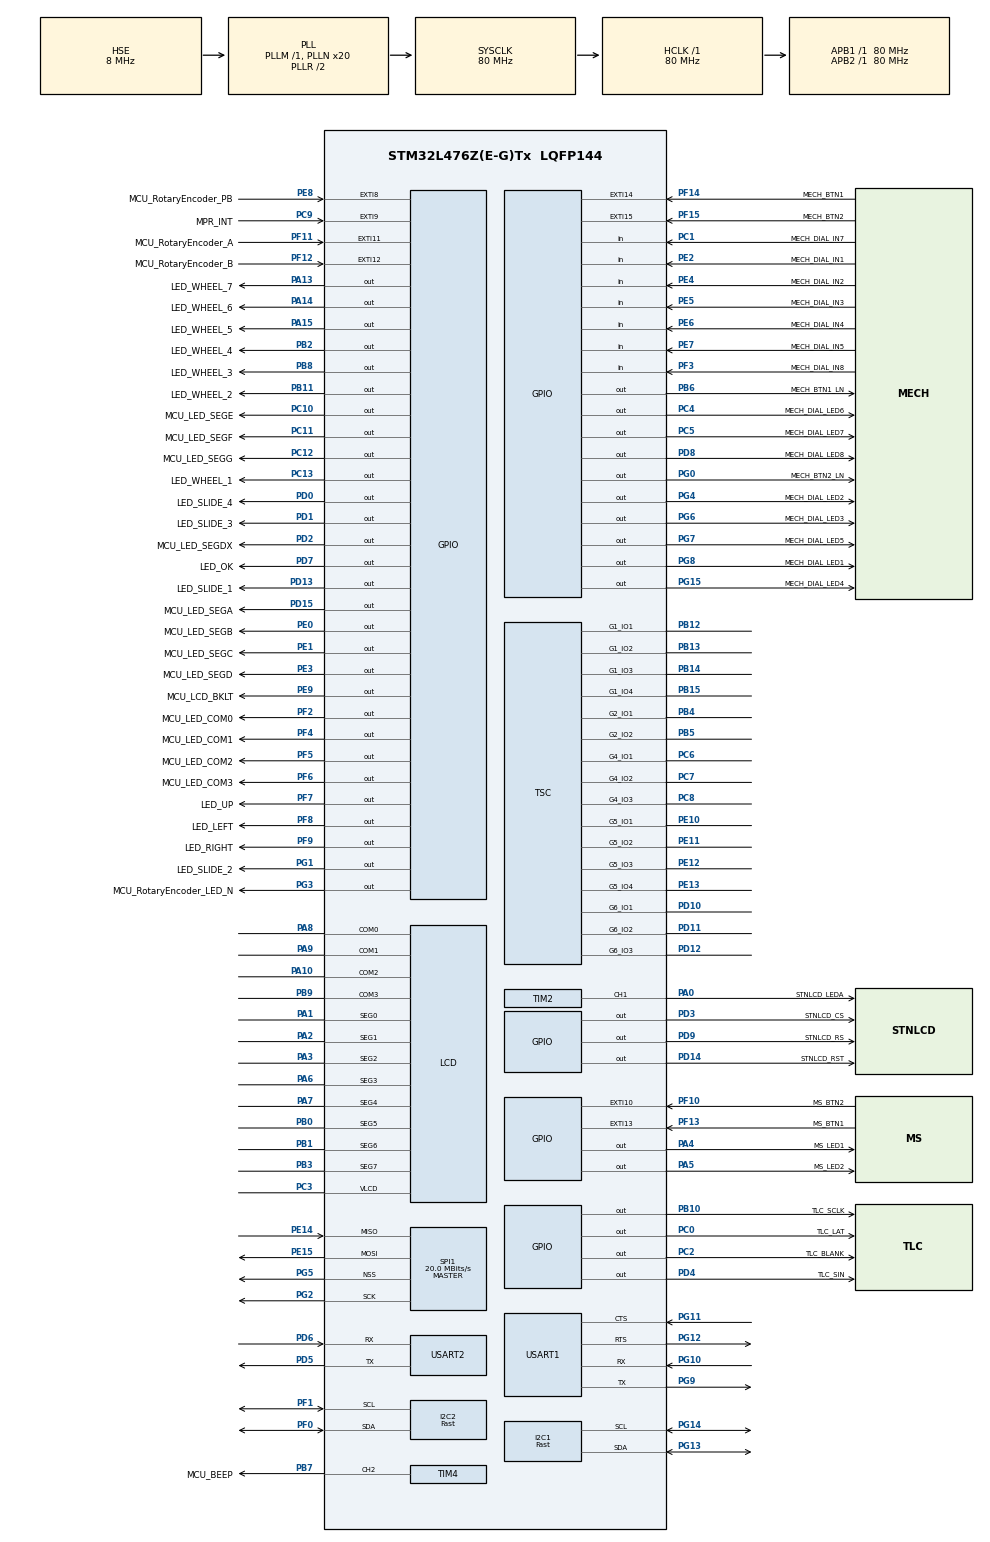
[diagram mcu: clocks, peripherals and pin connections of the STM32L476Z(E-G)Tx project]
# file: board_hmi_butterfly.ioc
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Dma.Request0=USART1_RX
Dma.Request1=USART2_RX
Dma.USART1_RX.0.Direction=DMA_PERIPH_TO_MEMORY
Dma.USART1_RX.0.Instance=DMA1_Channel5
Dma.USART1_RX.0.MemDataAlignment=DMA_MDATAALIGN_BYTE
Dma.USART1_RX.0.MemInc=DMA_MINC_ENABLE
Dma.USART1_RX.0.Mode=DMA_NORMAL
Dma.USART1_RX.0.PeriphDataAlignment=DMA_PDATAALIGN_BYTE
Dma.USART1_RX.0.PeriphInc=DMA_PINC_DISABLE
Dma.USART1_RX.0.Priority=DMA_PRIORITY_LOW
Dma.USART2_RX.1.Direction=DMA_PERIPH_TO_MEMORY
Dma.USART2_RX.1.Instance=DMA1_Channel6
Dma.USART2_RX.1.MemDataAlignment=DMA_MDATAALIGN_BYTE
Dma.USART2_RX.1.MemInc=DMA_MINC_ENABLE
Dma.USART2_RX.1.Mode=DMA_NORMAL
Dma.USART2_RX.1.PeriphDataAlignment=DMA_PDATAALIGN_BYTE
Dma.USART2_RX.1.PeriphInc=DMA_PINC_DISABLE
Dma.USART2_RX.1.Priority=DMA_PRIORITY_LOW
FREERTOS.Tasks01=defaultTask,0,128,StartDefaultTask,Default,NULL,Dynamic,NULL,NULL
FREERTOS.configCHECK_FOR_STACK_OVERFLOW=1
FREERTOS.configTIMER_TASK_PRIORITY=3
FREERTOS.configTOTAL_HEAP_SIZE=32768
FREERTOS.configUSE_TIMERS=1
I2C1.I2C_Speed_Mode=I2C_Fast
I2C1.Timing=0x00702991
I2C2.I2C_Speed_Mode=I2C_Fast
I2C2.Timing=0x00702991
LCD.Bias=LCD_BIAS_1_3
LCD.Contrast=LCD_CONTRASTLEVEL_5
LCD.Divider=LCD_DIVIDER_24
LCD.HighDrive=LCD_HIGHDRIVE_ENABLE
LCD.Prescaler=LCD_PRESCALER_4
Mcu.Family=STM32L4
Mcu.Name=STM32L476Z(E-G)Tx
Mcu.Package=LQFP144
NVIC.DMA1_Channel5_IRQn=true\:5\:0\:false\:false\:true\:true\:false
NVIC.DMA1_Channel6_IRQn=true\:5\:0\:false\:false\:true\:true\:false
NVIC.EXTI15_10_IRQn=true\:5\:0\:false\:false\:true\:true\:true
NVIC.EXTI9_5_IRQn=true\:5\:0\:false\:false\:true\:true\:true
NVIC.PriorityGroup=NVIC_PRIORITYGROUP_4
NVIC.RTC_Alarm_IRQn=true\:5\:0\:false\:false\:true\:true\:true
NVIC.USART1_IRQn=true\:5\:0\:false\:false\:true\:true\:true
NVIC.USART2_IRQn=true\:5\:0\:false\:false\:true\:true\:true
PA0.GPIO_Label=STNLCD_LEDA
PA0.Signal=S_TIM2_CH1
PA1.Mode=SEG0
PA1.Signal=LCD_SEG0
PA10.Mode=1/4 Duty Cycle
PA10.Signal=LCD_COM2
PA13\ (JTMS-SWDIO).GPIO_Label=LED_WHEEL_7
PA13\ (JTMS-SWDIO).GPIO_ModeDefaultOutputPP=GPIO_MODE_OUTPUT_OD
PA13\ (JTMS-SWDIO).PinState=GPIO_PIN_SET
PA13\ (JTMS-SWDIO).Signal=GPIO_Output
PA14\ (JTCK-SWCLK).GPIO_Label=LED_WHEEL_6
PA14\ (JTCK-SWCLK).GPIO_ModeDefaultOutputPP=GPIO_MODE_OUTPUT_OD
PA14\ (JTCK-SWCLK).PinState=GPIO_PIN_SET
PA14\ (JTCK-SWCLK).Signal=GPIO_Output
PA15\ (JTDI).GPIO_Label=LED_WHEEL_5
PA15\ (JTDI).GPIO_ModeDefaultOutputPP=GPIO_MODE_OUTPUT_OD
PA15\ (JTDI).PinState=GPIO_PIN_SET
PA15\ (JTDI).Signal=GPIO_Output
PA2.Mode=SEG1
PA2.Signal=LCD_SEG1
PA3.Mode=SEG2
PA3.Signal=LCD_SEG2
PA4.GPIO_Label=MS_LED1
PA4.GPIO_ModeDefaultOutputPP=GPIO_MODE_OUTPUT_OD
PA4.PinState=GPIO_PIN_SET
PA4.Signal=GPIO_Output
PA5.GPIO_Label=MS_LED2
PA5.GPIO_ModeDefaultOutputPP=GPIO_MODE_OUTPUT_OD
PA5.PinState=GPIO_PIN_SET
PA5.Signal=GPIO_Output
PA6.Mode=SEG3
PA6.Signal=LCD_SEG3
PA7.Mode=SEG4
PA7.Signal=LCD_SEG4
PA8.Mode=1/4 Duty Cycle
PA8.Signal=LCD_COM0
PA9.Mode=1/4 Duty Cycle
PA9.Signal=LCD_COM1
PB0.Mode=SEG5
PB0.Signal=LCD_SEG5
PB1.Mode=SEG6
PB1.Signal=LCD_SEG6
PB10.GPIO_Label=TLC_SCLK
PB10.GPIO_ModeDefaultOutputPP=GPIO_MODE_OUTPUT_OD
PB10.Signal=GPIO_Output
PB11.GPIO_Label=LED_WHEEL_2
PB11.GPIO_ModeDefaultOutputPP=GPIO_MODE_OUTPUT_OD
PB11.PinState=GPIO_PIN_SET
PB11.Signal=GPIO_Output
PB12.Mode=G1_IO1-Sampling
PB12.Signal=TSC_G1_IO1
PB13.Mode=G1_IO2-Channel
PB13.Signal=TSC_G1_IO2
PB14.Mode=G1_IO3-Channel
PB14.Signal=TSC_G1_IO3
PB15.Mode=G1_IO4-Channel
PB15.Signal=TSC_G1_IO4
PB2.GPIO_Label=LED_WHEEL_4
PB2.GPIO_ModeDefaultOutputPP=GPIO_MODE_OUTPUT_OD
PB2.PinState=GPIO_PIN_SET
PB2.Signal=GPIO_Output
PB3\ (JTDO-TRACESWO).Mode=SEG7
PB3\ (JTDO-TRACESWO).Signal=LCD_SEG7
PB4\ (NJTRST).Mode=G2_IO1-Sampling
PB4\ (NJTRST).Signal=TSC_G2_IO1
PB5.Mode=G2_IO2-Channel
PB5.Signal=TSC_G2_IO2
PB6.GPIO_Label=MECH_BTN1_LN
PB6.GPIO_ModeDefaultOutputPP=GPIO_MODE_OUTPUT_OD
PB6.PinState=GPIO_PIN_SET
PB6.Signal=GPIO_Output
PB7.GPIO_FM7=__NULL
PB7.GPIO_Label=MCU_BEEP
PB7.GPIO_ModeDefaultPP=GPIO_MODE_AF_PP
PB7.GPIO_Speed=GPIO_SPEED_FREQ_MEDIUM
PB7.Signal=S_TIM4_CH2
PB8.GPIO_Label=LED_WHEEL_3
PB8.GPIO_ModeDefaultOutputPP=GPIO_MODE_OUTPUT_OD
PB8.PinState=GPIO_PIN_SET
PB8.Signal=GPIO_Output
PB9.Mode=1/4 Duty Cycle
PB9.Signal=LCD_COM3
PC0.GPIO_Label=TLC_LAT
PC0.GPIO_ModeDefaultOutputPP=GPIO_MODE_OUTPUT_OD
PC0.Signal=GPIO_Output
PC1.GPIO_Label=MECH_DIAL_IN7
PC1.Signal=GPIO_Input
PC10.GPIO_Label=MCU_LED_SEGE
PC10.Signal=GPIO_Output
PC11.GPIO_Label=MCU_LED_SEGF
PC11.Signal=GPIO_Output
PC12.GPIO_Label=MCU_LED_SEGG
PC12.Signal=GPIO_Output
PC13.GPIO_Label=LED_WHEEL_1
PC13.GPIO_ModeDefaultOutputPP=GPIO_MODE_OUTPUT_OD
PC13.PinState=GPIO_PIN_SET
PC13.Signal=GPIO_Output
PC14-OSC32_IN\ (PC14).Mode=LSE-External-Oscillator
PC14-OSC32_IN\ (PC14).Signal=RCC_OSC32_IN
PC15-OSC32_OUT\ (PC15).Mode=LSE-External-Oscillator
PC15-OSC32_OUT\ (PC15).Signal=RCC_OSC32_OUT
PC2.GPIO_Label=TLC_BLANK
PC2.GPIO_ModeDefaultOutputPP=GPIO_MODE_OUTPUT_OD
PC2.GPIO_Speed=GPIO_SPEED_FREQ_LOW
PC2.PinState=GPIO_PIN_RESET
PC2.Signal=GPIO_Output
PC3.Mode=1/4 Duty Cycle
PC3.Signal=LCD_VLCD
PC4.GPIO_Label=MECH_DIAL_LED6
PC4.GPIO_ModeDefaultOutputPP=GPIO_MODE_OUTPUT_OD
PC4.PinState=GPIO_PIN_SET
PC4.Signal=GPIO_Output
PC5.GPIO_Label=MECH_DIAL_LED7
PC5.GPIO_ModeDefaultOutputPP=GPIO_MODE_OUTPUT_OD
PC5.PinState=GPIO_PIN_SET
PC5.Signal=GPIO_Output
PC6.Mode=G4_IO1-Sampling
PC6.Signal=TSC_G4_IO1
PC7.Mode=G4_IO2-Channel
PC7.Signal=TSC_G4_IO2
PC8.Mode=G4_IO3-Channel
PC8.Signal=TSC_G4_IO3
PC9.GPIO_Label=MPR_INT
PC9.GPIO_ModeDefaultEXTI=GPIO_MODE_IT_FALLING
PC9.Signal=GPXTI9
PD0.GPIO_Label=LED_SLIDE_4
PD0.GPIO_ModeDefaultOutputPP=GPIO_MODE_OUTPUT_OD
PD0.PinState=GPIO_PIN_SET
PD0.Signal=GPIO_Output
PD1.GPIO_Label=LED_SLIDE_3
PD1.GPIO_ModeDefaultOutputPP=GPIO_MODE_OUTPUT_OD
PD1.PinState=GPIO_PIN_SET
PD1.Signal=GPIO_Output
PD10.Mode=G6_IO1-Sampling
PD10.Signal=TSC_G6_IO1
PD11.Mode=G6_IO2-Channel
PD11.Signal=TSC_G6_IO2
PD12.Mode=G6_IO3-Channel
PD12.Signal=TSC_G6_IO3
PD13.GPIO_Label=LED_SLIDE_1
PD13.GPIO_ModeDefaultOutputPP=GPIO_MODE_OUTPUT_OD
PD13.PinState=GPIO_PIN_SET
PD13.Signal=GPIO_Output
PD14.GPIO_Label=STNLCD_RST
PD14.Signal=GPIO_Output
PD15.GPIO_Label=MCU_LED_SEGA
PD15.PinState=GPIO_PIN_RESET
PD15.Signal=GPIO_Output
PD2.GPIO_Label=MCU_LED_SEGDX
PD2.Signal=GPIO_Output
PD3.GPIO_Label=STNLCD_CS
PD3.Signal=GPIO_Output
PD4.GPIO_Label=TLC_SIN
PD4.Signal=GPIO_Output
PD5.Mode=Asynchronous
PD5.Signal=USART2_TX
PD6.Mode=Asynchronous
PD6.Signal=USART2_RX
PD7.GPIO_Label=LED_OK
PD7.GPIO_ModeDefaultOutputPP=GPIO_MODE_OUTPUT_OD
PD7.PinState=GPIO_PIN_SET
PD7.Signal=GPIO_Output
PD8.GPIO_Label=MECH_DIAL_LED8
PD8.GPIO_ModeDefaultOutputPP=GPIO_MODE_OUTPUT_OD
PD8.PinState=GPIO_PIN_SET
PD8.Signal=GPIO_Output
PD9.GPIO_Label=STNLCD_RS
PD9.Signal=GPIO_Output
PE0.GPIO_Label=MCU_LED_SEGB
PE0.Signal=GPIO_Output
PE1.GPIO_Label=MCU_LED_SEGC
PE1.Signal=GPIO_Output
PE10.Mode=G5_IO1-Sampling
PE10.Signal=TSC_G5_IO1
PE11.Mode=G5_IO2-Channel
PE11.Signal=TSC_G5_IO2
PE12.Mode=G5_IO3-Channel
PE12.Signal=TSC_G5_IO3
PE13.Mode=G5_IO4-Channel
PE13.Signal=TSC_G5_IO4
PE14.Mode=Full_Duplex_Master
PE14.Signal=SPI1_MISO
PE15.Mode=Full_Duplex_Master
PE15.Signal=SPI1_MOSI
PE2.GPIO_Label=MECH_DIAL_IN1
PE2.Signal=GPIO_Input
PE3.GPIO_Label=MCU_LED_SEGD
PE3.Signal=GPIO_Output
PE4.GPIO_Label=MECH_DIAL_IN2
PE4.Signal=GPIO_Input
PE5.GPIO_Label=MECH_DIAL_IN3
PE5.Signal=GPIO_Input
PE6.GPIO_Label=MECH_DIAL_IN4
PE6.Signal=GPIO_Input
PE7.GPIO_Label=MECH_DIAL_IN5
PE7.Signal=GPIO_Input
PE8.GPIO_Label=MCU_RotaryEncoder_PB
PE8.GPIO_ModeDefaultEXTI=GPIO_MODE_IT_RISING_FALLING
PE8.Signal=GPXTI8
PE9.GPIO_Label=MCU_LCD_BKLT
PE9.GPIO_PuPd=GPIO_NOPULL
PE9.Signal=GPIO_Output
PF0.Mode=I2C
PF0.Signal=I2C2_SDA
PF1.Mode=I2C
PF1.Signal=I2C2_SCL
PF10.GPIO_Label=MS_BTN2
PF10.GPIO_ModeDefaultEXTI=GPIO_MODE_IT_RISING_FALLING
PF10.Signal=GPXTI10
PF11.GPIO_Label=MCU_RotaryEncoder_A
PF11.GPIO_ModeDefaultEXTI=GPIO_MODE_IT_RISING_FALLING
PF11.Signal=GPXTI11
PF12.GPIO_Label=MCU_RotaryEncoder_B
PF12.GPIO_ModeDefaultEXTI=GPIO_MODE_IT_RISING_FALLING
PF12.Signal=GPXTI12
PF13.GPIO_Label=MS_BTN1
PF13.GPIO_ModeDefaultEXTI=GPIO_MODE_IT_RISING_FALLING
PF13.Signal=GPXTI13
PF14.GPIO_Label=MECH_BTN1
PF14.GPIO_ModeDefaultEXTI=GPIO_MODE_IT_RISING_FALLING
PF14.Signal=GPXTI14
PF15.GPIO_Label=MECH_BTN2
PF15.GPIO_ModeDefaultEXTI=GPIO_MODE_IT_RISING_FALLING
PF15.Signal=GPXTI15
PF2.GPIO_Label=MCU_LED_COM0
PF2.GPIO_Speed=GPIO_SPEED_FREQ_HIGH
PF2.PinState=GPIO_PIN_SET
PF2.Signal=GPIO_Output
PF3.GPIO_Label=MECH_DIAL_IN8
PF3.Signal=GPIO_Input
PF4.GPIO_Label=MCU_LED_COM1
PF4.GPIO_Speed=GPIO_SPEED_FREQ_HIGH
PF4.PinState=GPIO_PIN_SET
PF4.Signal=GPIO_Output
PF5.GPIO_Label=MCU_LED_COM2
PF5.GPIO_Speed=GPIO_SPEED_FREQ_HIGH
PF5.PinState=GPIO_PIN_SET
PF5.Signal=GPIO_Output
PF6.GPIO_Label=MCU_LED_COM3
PF6.GPIO_Speed=GPIO_SPEED_FREQ_HIGH
PF6.PinState=GPIO_PIN_SET
PF6.Signal=GPIO_Output
PF7.GPIO_Label=LED_UP
PF7.GPIO_ModeDefaultOutputPP=GPIO_MODE_OUTPUT_OD
PF7.PinState=GPIO_PIN_SET
PF7.Signal=GPIO_Output
PF8.GPIO_Label=LED_LEFT
PF8.GPIO_ModeDefaultOutputPP=GPIO_MODE_OUTPUT_OD
PF8.PinState=GPIO_PIN_SET
PF8.Signal=GPIO_Output
PF9.GPIO_Label=LED_RIGHT
PF9.GPIO_ModeDefaultOutputPP=GPIO_MODE_OUTPUT_OD
PF9.PinState=GPIO_PIN_SET
PF9.Signal=GPIO_Output
PG0.GPIO_Label=MECH_BTN2_LN
PG0.GPIO_ModeDefaultOutputPP=GPIO_MODE_OUTPUT_OD
PG0.PinState=GPIO_PIN_SET
PG0.Signal=GPIO_Output
PG1.GPIO_Label=LED_SLIDE_2
PG1.GPIO_ModeDefaultOutputPP=GPIO_MODE_OUTPUT_OD
PG1.PinState=GPIO_PIN_SET
PG1.Signal=GPIO_Output
PG10.Mode=Asynchronous
PG10.Signal=USART1_RX
PG11.Mode=CTS_RTS
PG11.Signal=USART1_CTS
PG12.Mode=CTS_RTS
PG12.Signal=USART1_RTS
PG13.Mode=I2C
PG13.Signal=I2C1_SDA
PG14.Mode=I2C
PG14.Signal=I2C1_SCL
PG15.GPIO_Label=MECH_DIAL_LED4
PG15.GPIO_ModeDefaultOutputPP=GPIO_MODE_OUTPUT_OD
PG15.PinState=GPIO_PIN_SET
PG15.Signal=GPIO_Output
PG2.Mode=Full_Duplex_Master
PG2.Signal=SPI1_SCK
PG3.GPIO_Label=MCU_RotaryEncoder_LED_N
PG3.GPIO_ModeDefaultOutputPP=GPIO_MODE_OUTPUT_OD
PG3.PinState=GPIO_PIN_SET
PG3.Signal=GPIO_Output
PG4.GPIO_Label=MECH_DIAL_LED2
PG4.GPIO_ModeDefaultOutputPP=GPIO_MODE_OUTPUT_OD
PG4.PinState=GPIO_PIN_SET
PG4.Signal=GPIO_Output
PG5.Mode=NSS_Signal_Hard_Output
PG5.Signal=SPI1_NSS
PG6.GPIO_Label=MECH_DIAL_LED3
PG6.GPIO_ModeDefaultOutputPP=GPIO_MODE_OUTPUT_OD
PG6.PinState=GPIO_PIN_SET
PG6.Signal=GPIO_Output
PG7.GPIO_Label=MECH_DIAL_LED5
PG7.GPIO_ModeDefaultOutputPP=GPIO_MODE_OUTPUT_OD
PG7.PinState=GPIO_PIN_SET
PG7.Signal=GPIO_Output
PG8.GPIO_Label=MECH_DIAL_LED1
PG8.GPIO_ModeDefaultOutputPP=GPIO_MODE_OUTPUT_OD
PG8.PinState=GPIO_PIN_SET
PG8.Signal=GPIO_Output
PG9.Mode=Asynchronous
PG9.Signal=USART1_TX
PH0-OSC_IN\ (PH0).Mode=HSE-External-Oscillator
PH0-OSC_IN\ (PH0).Signal=RCC_OSC_IN
PH1-OSC_OUT\ (PH1).Mode=HSE-External-Oscillator
PH1-OSC_OUT\ (PH1).Signal=RCC_OSC_OUT
ProjectManager.HeapSize=0x200
ProjectManager.StackSize=0x400
ProjectManager.TargetToolchain=MDK-ARM V5
RCC.ADCFreq_Value=32000000
RCC.AHBFreq_Value=80000000
RCC.APB1Freq_Value=80000000
RCC.APB1TimFreq_Value=80000000
RCC.APB2Freq_Value=80000000
RCC.APB2TimFreq_Value=80000000
RCC.CortexFreq_Value=80000000
RCC.HCLKFreq_Value=80000000
RCC.HSE_VALUE=8000000
RCC.HSI_VALUE=16000000
RCC.MSI_VALUE=4000000
RCC.PLLN=20
RCC.PLLSourceVirtual=RCC_PLLSOURCE_HSE
RCC.RTCClockSelection=RCC_RTCCLKSOURCE_LSE
RCC.SYSCLKFreq_VALUE=80000000
RCC.SYSCLKSource=RCC_SYSCLKSOURCE_PLLCLK
RCC.USBFreq_Value=32000000
RCC.VCOOutputFreq_Value=160000000
RTC.Alarm-Alarm\ A=RTC_ALARM_A
RTC.AlarmMaskDateWeekDay-Alarm\ A=RTC_ALARMMASK_DATEWEEKDAY
RTC.AlarmMaskHours-Alarm\ A=RTC_ALARMMASK_HOURS
RTC.Date=9
RTC.Month=RTC_MONTH_JULY
RTC.WeekDay=RTC_WEEKDAY_MONDAY
RTC.Year=18
SH.S_TIM2_CH1.0=TIM2_CH1,PWM Generation1 CH1
SH.S_TIM4_CH2.0=TIM4_CH2,PWM Generation2 CH2
SPI1.BaudRatePrescaler=SPI_BAUDRATEPRESCALER_4
SPI1.CalculateBaudRate=20.0 MBits/s
SPI1.DataSize=SPI_DATASIZE_8BIT
SPI1.Direction=SPI_DIRECTION_2LINES
SPI1.Mode=SPI_MODE_MASTER
SPI1.VirtualNSS=VM_NSSHARD
SPI1.VirtualType=VM_MASTER
TIM2.Channel-PWM\ Generation1\ CH1=TIM_CHANNEL_1
TIM2.Period=100-1
TIM2.Prescaler=2000-1
TIM4.Channel-PWM\ Generation2\ CH2=TIM_CHANNEL_2
TIM4.Period=100-1
TIM4.Prescaler=200-1
TIM4.Pulse-PWM\ Generation2\ CH2=50
TSC.CTPulseHighLength=TSC_CTPH_8CYCLES
TSC.CTPulseLowLength=TSC_CTPL_8CYCLES
TSC.ChannelIOs-G1_IO2=TSC_GROUP1_IO2
TSC.ChannelIOs-G1_IO3=TSC_GROUP1_IO3
TSC.ChannelIOs-G1_IO4=TSC_GROUP1_IO4
TSC.ChannelIOs-G2_IO2=TSC_GROUP2_IO2
TSC.ChannelIOs-G4_IO2=TSC_GROUP4_IO2
TSC.ChannelIOs-G4_IO3=TSC_GROUP4_IO3
TSC.ChannelIOs-G5_IO2=TSC_GROUP5_IO2
TSC.ChannelIOs-G5_IO3=TSC_GROUP5_IO3
TSC.ChannelIOs-G5_IO4=TSC_GROUP5_IO4
TSC.ChannelIOs-G6_IO2=TSC_GROUP6_IO2
TSC.ChannelIOs-G6_IO3=TSC_GROUP6_IO3
TSC.MaxCountValue=TSC_MCV_8191
TSC.PulseGeneratorPrescaler=TSC_PG_PRESC_DIV4
TSC.SamplingIOs-G1_IO1=TSC_GROUP1_IO1
TSC.SamplingIOs-G2_IO1=TSC_GROUP2_IO1
TSC.SamplingIOs-G4_IO1=TSC_GROUP4_IO1
TSC.SamplingIOs-G5_IO1=TSC_GROUP5_IO1
TSC.SamplingIOs-G6_IO1=TSC_GROUP6_IO1
TSC.SpreadSpectrum=DISABLE
TSC.SpreadSpectrumDeviation=127
USART1.VirtualMode-Asynchronous=VM_ASYNC
USART1.WordLength=WORDLENGTH_8B
USART2.VirtualMode-Asynchronous=VM_ASYNC
USART2.WordLength=WORDLENGTH_8B
VP_FREERTOS_VS_ENABLE.Mode=Enabled
VP_RTC_VS_RTC_Activate.Mode=RTC_Enabled
VP_RTC_VS_RTC_Alarm_A_Intern.Mode=Alarm A
VP_RTC_VS_RTC_Calendar.Mode=RTC_Calendar
board=board_hmi_butterfly

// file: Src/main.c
/**
  ******************************************************************************
  * File Name          : main.c
  * Description        : Main program body
  ******************************************************************************
  * This notice applies to any and all portions of this file
  * that are not between comment pairs USER CODE BEGIN and
  * USER CODE END. Other portions of this file, whether
  * inserted by the user or by software development tools
  * are owned by their respective copyright owners.
  *
  * Copyright (c) 2018 STMicroelectronics International N.V.
  * All rights reserved.
  *
  * Redistribution and use in source and binary forms, with or without
  * modification, are permitted, provided that the following conditions are met:
  *
  * 1. Redistribution of source code must retain the above copyright notice,
  *    this list of conditions and the following disclaimer.
  * 2. Redistributions in binary form must reproduce the above copyright notice,
  *    this list of conditions and the following disclaimer in the documentation
  *    and/or other materials provided with the distribution.
  * 3. Neither the name of STMicroelectronics nor the names of other
  *    contributors to this software may be used to endorse or promote products
  *    derived from this software without specific written permission.
  * 4. This software, including modifications and/or derivative works of this
  *    software, must execute solely and exclusively on microcontroller or
  *    microprocessor devices manufactured by or for STMicroelectronics.
  * 5. Redistribution and use of this software other than as permitted under
  *    this license is void and will automatically terminate your rights under
  *    this license.
  *
  * THIS SOFTWARE IS PROVIDED BY STMICROELECTRONICS AND CONTRIBUTORS "AS IS"
  * AND ANY EXPRESS, IMPLIED OR STATUTORY WARRANTIES, INCLUDING, BUT NOT
  * LIMITED TO, THE IMPLIED WARRANTIES OF MERCHANTABILITY, FITNESS FOR A
  * PARTICULAR PURPOSE AND NON-INFRINGEMENT OF THIRD PARTY INTELLECTUAL PROPERTY
  * RIGHTS ARE DISCLAIMED TO THE FULLEST EXTENT PERMITTED BY LAW. IN NO EVENT
  * SHALL STMICROELECTRONICS OR CONTRIBUTORS BE LIABLE FOR ANY DIRECT, INDIRECT,
  * INCIDENTAL, SPECIAL, EXEMPLARY, OR CONSEQUENTIAL DAMAGES (INCLUDING, BUT NOT
  * LIMITED TO, PROCUREMENT OF SUBSTITUTE GOODS OR SERVICES; LOSS OF USE, DATA,
  * OR PROFITS; OR BUSINESS INTERRUPTION) HOWEVER CAUSED AND ON ANY THEORY OF
  * LIABILITY, WHETHER IN CONTRACT, STRICT LIABILITY, OR TORT (INCLUDING
  * NEGLIGENCE OR OTHERWISE) ARISING IN ANY WAY OUT OF THE USE OF THIS SOFTWARE,
  * EVEN IF ADVISED OF THE POSSIBILITY OF SUCH DAMAGE.
  *
  ******************************************************************************
  */

#include "main.h"
#include "stm32l4xx_hal.h"
#include "cmsis_os.h"
#include "dma.h"
#include "i2c.h"
#include "lcd.h"
#include "rtc.h"
#include "spi.h"
#include "tim.h"
#include "tsc.h"
#include "usart.h"
#include "gpio.h"

/* USER CODE BEGIN Includes */
#include "flex_common.h"
#include "flex_platform.h"
#include "flex_app_segdisp.h"
#include "nvms.h"

/*========================================================================================================
										D E B U G----start
========================================================================================================*/
#ifndef MOD_NAME
#define MOD_NAME								"[MAIN]--"
#endif

#if defined(__FLEX_TRACE_ENABLE__)
#define TRACE_F(fmt, arg...)				DBG_MSG(MOD_NAME "[F]--%s.\r\n", __func__)
#define TRACE_I(fmt, arg...)				DBG_MSG(MOD_NAME "[I]--" fmt, ##arg)
#define TRACE_W(fmt, arg...)				DBG_MSG(MOD_NAME "[W]--" fmt, ##arg)
#else
#define TRACE_F()										//do{}while(0)
#define TRACE_I(fmt, arg...)				//do{}while(0)
#define TRACE_W(fmt, arg...)				//do{}while(0)
#endif
#define TRACE_E(fmt, arg...)				DBG_MSG(MOD_NAME "[E]--" fmt, ##arg)

/*========================================================================================================
										D E B U G----end
========================================================================================================*/

/* USER CODE END Includes */

/* USER CODE BEGIN PV */
/* Private variables ---------------------------------------------------------*/

/* USER CODE END PV */

void SystemClock_Config(void);
void MX_FREERTOS_Init(void);

/* USER CODE BEGIN PFP */
/* Private function prototypes -----------------------------------------------*/

/* USER CODE END PFP */

/* USER CODE BEGIN 0 */
#define PUTCHAR_PROTOTYPE int fputc(int ch, FILE *f)
PUTCHAR_PROTOTYPE
{
  /* Place your implementation of fputc here */
  /* e.g. write a character to the EVAL_COM1 and Loop until the end of transmission */
  HAL_UART_Transmit(&huart2, (uint8_t *)&ch, 1, 0xFFFF);

  return ch;
}

#if( configUSE_TICK_HOOK > 0 )
void vApplicationTickHook( void )
{
#if (LED_SEGMENT_DISP_LEVEL)
	  LedSegRefreshHandler();
#endif
}
#endif

/* USER CODE END 0 */

int main(void)
{

  /* MCU Configuration----------------------------------------------------------*/

  /* Reset of all peripherals, Initializes the Flash interface and the Systick. */
  HAL_Init();

  /* Configure the system clock */
  SystemClock_Config();

  /* Initialize all configured peripherals */
  MX_GPIO_Init();
  MX_DMA_Init();
  MX_LCD_Init();
  MX_USART1_UART_Init();
  MX_USART2_UART_Init();
  MX_RTC_Init();
  MX_I2C2_Init();
  MX_SPI1_Init();
  MX_TIM2_Init();
  MX_TSC_Init();
  MX_I2C1_Init();
  MX_TIM4_Init();

  /* USER CODE BEGIN 2 */
  nvms_init();
  RTC_AlarmInit();
  /* USER CODE END 2 */

  /* Call init function for freertos objects (in freertos.c) */
  MX_FREERTOS_Init();

  /* Start scheduler */
  osKernelStart();

  /* We should never get here as control is now taken by the scheduler */

  /* Infinite loop */
  while (1)
  {

  }

}

/** System Clock Configuration
*/
void SystemClock_Config(void)
{

  RCC_OscInitTypeDef RCC_OscInitStruct;
  RCC_ClkInitTypeDef RCC_ClkInitStruct;
  RCC_PeriphCLKInitTypeDef PeriphClkInit;

    /**Configure LSE Drive Capability
    */
  __HAL_RCC_LSEDRIVE_CONFIG(RCC_LSEDRIVE_LOW);

    /**Initializes the CPU, AHB and APB busses clocks
    */
  RCC_OscInitStruct.OscillatorType = RCC_OSCILLATORTYPE_HSE|RCC_OSCILLATORTYPE_LSE;
  RCC_OscInitStruct.HSEState = RCC_HSE_ON;
  RCC_OscInitStruct.LSEState = RCC_LSE_ON;
  RCC_OscInitStruct.PLL.PLLState = RCC_PLL_ON;
  RCC_OscInitStruct.PLL.PLLSource = RCC_PLLSOURCE_HSE;
  RCC_OscInitStruct.PLL.PLLM = 1;
  RCC_OscInitStruct.PLL.PLLN = 20;
  RCC_OscInitStruct.PLL.PLLP = RCC_PLLP_DIV7;
  RCC_OscInitStruct.PLL.PLLQ = RCC_PLLQ_DIV2;
  RCC_OscInitStruct.PLL.PLLR = RCC_PLLR_DIV2;
  if (HAL_RCC_OscConfig(&RCC_OscInitStruct) != HAL_OK)
  {
    _Error_Handler(__FILE__, __LINE__);
  }

    /**Initializes the CPU, AHB and APB busses clocks
    */
  RCC_ClkInitStruct.ClockType = RCC_CLOCKTYPE_HCLK|RCC_CLOCKTYPE_SYSCLK
                              |RCC_CLOCKTYPE_PCLK1|RCC_CLOCKTYPE_PCLK2;
  RCC_ClkInitStruct.SYSCLKSource = RCC_SYSCLKSOURCE_PLLCLK;
  RCC_ClkInitStruct.AHBCLKDivider = RCC_SYSCLK_DIV1;
  RCC_ClkInitStruct.APB1CLKDivider = RCC_HCLK_DIV1;
  RCC_ClkInitStruct.APB2CLKDivider = RCC_HCLK_DIV1;

  if (HAL_RCC_ClockConfig(&RCC_ClkInitStruct, FLASH_LATENCY_3) != HAL_OK)
  {
    _Error_Handler(__FILE__, __LINE__);
  }

  PeriphClkInit.PeriphClockSelection = RCC_PERIPHCLK_RTC|RCC_PERIPHCLK_USART1
                              |RCC_PERIPHCLK_USART2|RCC_PERIPHCLK_I2C1
                              |RCC_PERIPHCLK_I2C2;
  PeriphClkInit.Usart1ClockSelection = RCC_USART1CLKSOURCE_PCLK2;
  PeriphClkInit.Usart2ClockSelection = RCC_USART2CLKSOURCE_PCLK1;
  PeriphClkInit.I2c1ClockSelection = RCC_I2C1CLKSOURCE_PCLK1;
  PeriphClkInit.I2c2ClockSelection = RCC_I2C2CLKSOURCE_PCLK1;
  PeriphClkInit.RTCClockSelection = RCC_RTCCLKSOURCE_LSE;
  if (HAL_RCCEx_PeriphCLKConfig(&PeriphClkInit) != HAL_OK)
  {
    _Error_Handler(__FILE__, __LINE__);
  }

    /**Configure the main internal regulator output voltage
    */
  if (HAL_PWREx_ControlVoltageScaling(PWR_REGULATOR_VOLTAGE_SCALE1) != HAL_OK)
  {
    _Error_Handler(__FILE__, __LINE__);
  }

    /**Configure the Systick interrupt time
    */
  HAL_SYSTICK_Config(HAL_RCC_GetHCLKFreq()/1000);

    /**Configure the Systick
    */
  HAL_SYSTICK_CLKSourceConfig(SYSTICK_CLKSOURCE_HCLK);

  /* SysTick_IRQn interrupt configuration */
  HAL_NVIC_SetPriority(SysTick_IRQn, 15, 0);
}

void _Error_Handler(char * file, int line)
{
  while(1)
  {
  }
}

#ifdef USE_FULL_ASSERT

/**
   * @brief Reports the name of the source file and the source line number
   * where the assert_param error has occurred.
   * @param file: pointer to the source file name
   * @param line: assert_param error line source number
   * @retval None
   */
void assert_failed(uint8_t* file, uint32_t line)
{
  /* USER CODE BEGIN 6 */
  /* User can add his own implementation to report the file name and line number,
    ex: printf("Wrong parameters value: file %s on line %d\r\n", file, line) */
	TRACE_E("ASSERT: file %s on line %d\r\n", file, line);
  /* USER CODE END 6 */

}

#endif

/************************ (C) COPYRIGHT STMicroelectronics *****END OF FILE****/

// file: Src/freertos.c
/**
  ******************************************************************************
  * File Name          : freertos.c
  * Description        : Code for freertos applications
  ******************************************************************************
  * This notice applies to any and all portions of this file
  * that are not between comment pairs USER CODE BEGIN and
  * USER CODE END. Other portions of this file, whether
  * inserted by the user or by software development tools
  * are owned by their respective copyright owners.
  *
  * Copyright (c) 2018 STMicroelectronics International N.V.
  * All rights reserved.
  *
  * Redistribution and use in source and binary forms, with or without
  * modification, are permitted, provided that the following conditions are met:
  *
  * 1. Redistribution of source code must retain the above copyright notice,
  *    this list of conditions and the following disclaimer.
  * 2. Redistributions in binary form must reproduce the above copyright notice,
  *    this list of conditions and the following disclaimer in the documentation
  *    and/or other materials provided with the distribution.
  * 3. Neither the name of STMicroelectronics nor the names of other
  *    contributors to this software may be used to endorse or promote products
  *    derived from this software without specific written permission.
  * 4. This software, including modifications and/or derivative works of this
  *    software, must execute solely and exclusively on microcontroller or
  *    microprocessor devices manufactured by or for STMicroelectronics.
  * 5. Redistribution and use of this software other than as permitted under
  *    this license is void and will automatically terminate your rights under
  *    this license.
  *
  * THIS SOFTWARE IS PROVIDED BY STMICROELECTRONICS AND CONTRIBUTORS "AS IS"
  * AND ANY EXPRESS, IMPLIED OR STATUTORY WARRANTIES, INCLUDING, BUT NOT
  * LIMITED TO, THE IMPLIED WARRANTIES OF MERCHANTABILITY, FITNESS FOR A
  * PARTICULAR PURPOSE AND NON-INFRINGEMENT OF THIRD PARTY INTELLECTUAL PROPERTY
  * RIGHTS ARE DISCLAIMED TO THE FULLEST EXTENT PERMITTED BY LAW. IN NO EVENT
  * SHALL STMICROELECTRONICS OR CONTRIBUTORS BE LIABLE FOR ANY DIRECT, INDIRECT,
  * INCIDENTAL, SPECIAL, EXEMPLARY, OR CONSEQUENTIAL DAMAGES (INCLUDING, BUT NOT
  * LIMITED TO, PROCUREMENT OF SUBSTITUTE GOODS OR SERVICES; LOSS OF USE, DATA,
  * OR PROFITS; OR BUSINESS INTERRUPTION) HOWEVER CAUSED AND ON ANY THEORY OF
  * LIABILITY, WHETHER IN CONTRACT, STRICT LIABILITY, OR TORT (INCLUDING
  * NEGLIGENCE OR OTHERWISE) ARISING IN ANY WAY OUT OF THE USE OF THIS SOFTWARE,
  * EVEN IF ADVISED OF THE POSSIBILITY OF SUCH DAMAGE.
  *
  ******************************************************************************
  */

#include "FreeRTOS.h"
#include "task.h"
#include "cmsis_os.h"

/* USER CODE BEGIN Includes */
#include "flex_common.h"
#include "flex_app.h"
#include "flex_drv_panel.h"
#include "flex_drv_button.h"
#include "flex_framework_input.h"
#include "flex_app_segdisp.h"
#include "flex_app_osd_application.h"
#include "flex_app_blotter.h"
#include "flex_framework_esp32.h"
#include "flex_hal.h"
#include "flex_drv.h"
#include "flex_drv_beeper.h"
#include "flex_framework_privtocol.h"
/*========================================================================================================
										D E B U G
========================================================================================================*/
#ifndef MOD_NAME
#define MOD_NAME								"[FreeRTOS]--"
#endif

#if defined(__FLEX_TRACE_ENABLE__)
#define TRACE_F(fmt, arg...)				DBG_MSG(MOD_NAME "[F]--%s.\r\n", __func__)
#define TRACE_I(fmt, arg...)				DBG_MSG(MOD_NAME "[I]--" fmt, ##arg)
#define TRACE_W(fmt, arg...)				DBG_MSG(MOD_NAME "[W]--" fmt, ##arg)
#else
#define TRACE_F()										//do{}while(0)
#define TRACE_I(fmt, arg...)				//do{}while(0)
#define TRACE_W(fmt, arg...)				//do{}while(0)
#endif
#define TRACE_E(fmt, arg...)				DBG_MSG(MOD_NAME "[E]--" fmt, ##arg)

/*========================================================================================================
										E X T E R N
========================================================================================================*/

/*========================================================================================================
										D E F I N E
========================================================================================================*/

/*========================================================================================================
										T Y P E D E F
========================================================================================================*/

/* USER CODE END Includes */

osThreadId defaultTaskHandle;

void StartDefaultTask(void const * argument);

void MX_FREERTOS_Init(void); /* (MISRA C 2004 rule 8.1) */

/* Hook prototypes */
void vApplicationStackOverflowHook(xTaskHandle xTask, signed char *pcTaskName);

/* USER CODE BEGIN 4 */
__weak void vApplicationStackOverflowHook(xTaskHandle xTask, signed char *pcTaskName)
{
   /* Run time stack overflow checking is performed if
   configCHECK_FOR_STACK_OVERFLOW is defined to 1 or 2. This hook function is
   called if a stack overflow is detected. */
   DBG_MSG("%s caused by %s\n",__FUNCTION__,pcTaskName);
   while(1)
   {
   }
}
/* USER CODE END 4 */

/* Init FreeRTOS */

void MX_FREERTOS_Init(void) {

  /* Create the thread(s) */
  /* definition and creation of defaultTask */
  osThreadDef(defaultTask, StartDefaultTask, osPriorityNormal, 0, 128);
  defaultTaskHandle = osThreadCreate(osThread(defaultTask), NULL);

  /* USER CODE BEGIN RTOS_THREADS */
  //interrupt is disabled till after osKernelStart()
  osThreadDef(SegDisplayTask, StartSegDisplayTask, osPriorityNormal, 0, 128);
  osThreadCreate(osThread(SegDisplayTask), NULL);
  /* USER CODE END RTOS_THREADS */

}

/* StartDefaultTask function */
void StartDefaultTask(void const * argument)
{

  /* USER CODE BEGIN StartDefaultTask */
  TRACE_F();

  /* add threads, ... */
#if (PROJECT_SELECT==PROJECT_HMI_BUTTERFLY)
  TRACE_I("========================================================\r\n");
  TRACE_I("                        power on                        \r\n");
  TRACE_I("========================================================\r\n");
  TRACE_I("SW_VERSION=%s \r\n", SW_VERSION);

  Flex_Hal_Init();
  Flex_Drv_Init();

  //ESP32 Init
  ESP32_Init();
  Privtocol_Init();
  /* definition and creation of SegDisplayTask */

//-----------------------carson add start
  osThreadDef(MiscTask, App_Misc_Task, osPriorityLow, 0, 128);
  osThreadCreate(osThread(MiscTask), NULL);

  osThreadDef(AppKeyTask, App_Key_Task, osPriorityLow, 0, 128);
  osThreadCreate(osThread(AppKeyTask), NULL);

  osThreadDef(TscTask, App_Tsc_Task, osPriorityLow, 0, 128);
  osThreadCreate(osThread(TscTask), NULL);

  osThreadDef(BlotterTask, App_Blotter_Task, osPriorityLow, 0, 256);
  osThreadCreate(osThread(BlotterTask), NULL);

  osThreadDef(OsdTask, App_Osd_Task, osPriorityLow, 0, 256);
  osThreadCreate(osThread(OsdTask), NULL);

  osThreadDef(InputTask, Frm_Input_Task, osPriorityLow, 0, 128);
  osThreadCreate(osThread(InputTask), NULL);
//-----------------------carson add end

#endif

#if 1
	osThreadTerminate(osThreadGetId());
#else
  /* Infinite loop */
  for(;;)
  {
    osDelay(1);
  }
#endif
  /* USER CODE END StartDefaultTask */
}

/************************ (C) COPYRIGHT STMicroelectronics *****END OF FILE****/
